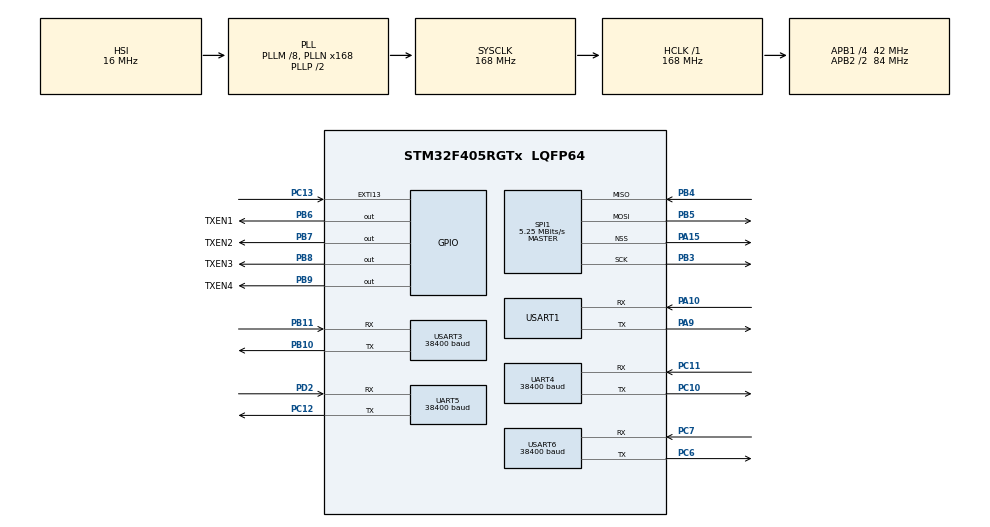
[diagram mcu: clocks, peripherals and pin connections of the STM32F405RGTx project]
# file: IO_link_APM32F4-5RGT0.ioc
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Dma.Request0=USART1_TX
Dma.Request1=USART1_RX
Dma.Request2=UART5_RX
Dma.Request3=UART4_RX
Dma.Request4=USART3_RX
Dma.Request5=USART6_RX
Dma.UART4_RX.3.Direction=DMA_PERIPH_TO_MEMORY
Dma.UART4_RX.3.FIFOMode=DMA_FIFOMODE_DISABLE
Dma.UART4_RX.3.Instance=DMA1_Stream2
Dma.UART4_RX.3.MemDataAlignment=DMA_MDATAALIGN_BYTE
Dma.UART4_RX.3.MemInc=DMA_MINC_ENABLE
Dma.UART4_RX.3.Mode=DMA_CIRCULAR
Dma.UART4_RX.3.PeriphDataAlignment=DMA_PDATAALIGN_BYTE
Dma.UART4_RX.3.PeriphInc=DMA_PINC_DISABLE
Dma.UART4_RX.3.Priority=DMA_PRIORITY_LOW
Dma.UART5_RX.2.Direction=DMA_PERIPH_TO_MEMORY
Dma.UART5_RX.2.FIFOMode=DMA_FIFOMODE_DISABLE
Dma.UART5_RX.2.Instance=DMA1_Stream0
Dma.UART5_RX.2.MemDataAlignment=DMA_MDATAALIGN_BYTE
Dma.UART5_RX.2.MemInc=DMA_MINC_ENABLE
Dma.UART5_RX.2.Mode=DMA_CIRCULAR
Dma.UART5_RX.2.PeriphDataAlignment=DMA_PDATAALIGN_BYTE
Dma.UART5_RX.2.PeriphInc=DMA_PINC_DISABLE
Dma.UART5_RX.2.Priority=DMA_PRIORITY_LOW
Dma.USART1_RX.1.Direction=DMA_PERIPH_TO_MEMORY
Dma.USART1_RX.1.FIFOMode=DMA_FIFOMODE_DISABLE
Dma.USART1_RX.1.Instance=DMA2_Stream2
Dma.USART1_RX.1.MemDataAlignment=DMA_MDATAALIGN_BYTE
Dma.USART1_RX.1.MemInc=DMA_MINC_ENABLE
Dma.USART1_RX.1.Mode=DMA_CIRCULAR
Dma.USART1_RX.1.PeriphDataAlignment=DMA_PDATAALIGN_BYTE
Dma.USART1_RX.1.PeriphInc=DMA_PINC_DISABLE
Dma.USART1_RX.1.Priority=DMA_PRIORITY_LOW
Dma.USART1_TX.0.Direction=DMA_MEMORY_TO_PERIPH
Dma.USART1_TX.0.FIFOMode=DMA_FIFOMODE_DISABLE
Dma.USART1_TX.0.Instance=DMA2_Stream7
Dma.USART1_TX.0.MemDataAlignment=DMA_MDATAALIGN_BYTE
Dma.USART1_TX.0.MemInc=DMA_MINC_ENABLE
Dma.USART1_TX.0.Mode=DMA_CIRCULAR
Dma.USART1_TX.0.PeriphDataAlignment=DMA_PDATAALIGN_BYTE
Dma.USART1_TX.0.PeriphInc=DMA_PINC_DISABLE
Dma.USART1_TX.0.Priority=DMA_PRIORITY_LOW
Dma.USART3_RX.4.Direction=DMA_PERIPH_TO_MEMORY
Dma.USART3_RX.4.FIFOMode=DMA_FIFOMODE_DISABLE
Dma.USART3_RX.4.Instance=DMA1_Stream1
Dma.USART3_RX.4.MemDataAlignment=DMA_MDATAALIGN_BYTE
Dma.USART3_RX.4.MemInc=DMA_MINC_ENABLE
Dma.USART3_RX.4.Mode=DMA_CIRCULAR
Dma.USART3_RX.4.PeriphDataAlignment=DMA_PDATAALIGN_BYTE
Dma.USART3_RX.4.PeriphInc=DMA_PINC_DISABLE
Dma.USART3_RX.4.Priority=DMA_PRIORITY_LOW
Dma.USART6_RX.5.Direction=DMA_PERIPH_TO_MEMORY
Dma.USART6_RX.5.FIFOMode=DMA_FIFOMODE_DISABLE
Dma.USART6_RX.5.Instance=DMA2_Stream1
Dma.USART6_RX.5.MemDataAlignment=DMA_MDATAALIGN_BYTE
Dma.USART6_RX.5.MemInc=DMA_MINC_ENABLE
Dma.USART6_RX.5.Mode=DMA_CIRCULAR
Dma.USART6_RX.5.PeriphDataAlignment=DMA_PDATAALIGN_BYTE
Dma.USART6_RX.5.PeriphInc=DMA_PINC_DISABLE
Dma.USART6_RX.5.Priority=DMA_PRIORITY_LOW
FREERTOS.Tasks01=defaultTask,24,128,StartDefaultTask,Default,NULL,Dynamic,NULL,NULL;DT35_1_App_task,24,256,DT35_1_App_Task,As external,NULL,Dynamic,NULL,NULL;DT35_2_App_task,24,256,DT35_2_App_Task,As external,NULL,Dynamic,NULL,NULL;DT35_3_App_task,24,256,DT35_3_App_Task,As external,NULL,Dynamic,NULL,NULL;DT35_4_App_task,24,256,DT35_4_App_Task,As external,NULL,Dynamic,NULL,NULL;DT35_App_task,24,256,DT35_App_Task,As external,NULL,Dynamic,NULL,NULL
Mcu.Family=STM32F4
Mcu.Name=STM32F405RGTx
Mcu.Package=LQFP64
NVIC.DMA1_Stream0_IRQn=true\:5\:0\:false\:false\:true\:true\:false\:true\:true
NVIC.DMA1_Stream1_IRQn=true\:5\:0\:false\:false\:true\:true\:false\:true\:true
NVIC.DMA1_Stream2_IRQn=true\:5\:0\:false\:false\:true\:true\:false\:true\:true
NVIC.DMA2_Stream1_IRQn=true\:5\:0\:false\:false\:true\:true\:false\:true\:true
NVIC.DMA2_Stream2_IRQn=true\:5\:0\:false\:false\:true\:true\:false\:true\:true
NVIC.DMA2_Stream7_IRQn=true\:5\:0\:false\:false\:true\:true\:false\:true\:true
NVIC.PriorityGroup=NVIC_PRIORITYGROUP_4
NVIC.SPI1_IRQn=true\:5\:0\:false\:false\:true\:true\:true\:true\:true
NVIC.TIM4_IRQn=true\:15\:0\:false\:false\:true\:false\:false\:true\:true
NVIC.TimeBase=TIM4_IRQn
NVIC.TimeBaseIP=TIM4
NVIC.USART1_IRQn=true\:5\:0\:false\:false\:true\:true\:true\:true\:true
PA10.Mode=Asynchronous
PA10.Signal=USART1_RX
PA13.Mode=Serial_Wire
PA13.Signal=SYS_JTMS-SWDIO
PA14.Mode=Serial_Wire
PA14.Signal=SYS_JTCK-SWCLK
PA15.Mode=NSS_Signal_Hard_Output
PA15.Signal=SPI1_NSS
PA9.Mode=Asynchronous
PA9.Signal=USART1_TX
PB10.Mode=Asynchronous
PB10.Signal=USART3_TX
PB11.Mode=Asynchronous
PB11.Signal=USART3_RX
PB3.Mode=Full_Duplex_Master
PB3.Signal=SPI1_SCK
PB4.Mode=Full_Duplex_Master
PB4.Signal=SPI1_MISO
PB5.Mode=Full_Duplex_Master
PB5.Signal=SPI1_MOSI
PB6.GPIO_Label=TXEN1
PB6.Signal=GPIO_Output
PB7.GPIO_Label=TXEN2
PB7.Signal=GPIO_Output
PB8.GPIO_Label=TXEN3
PB8.Signal=GPIO_Output
PB9.GPIO_Label=TXEN4
PB9.Signal=GPIO_Output
PC10.Mode=Asynchronous
PC10.Signal=UART4_TX
PC11.Mode=Asynchronous
PC11.Signal=UART4_RX
PC12.Mode=Asynchronous
PC12.Signal=UART5_TX
PC13-ANTI_TAMP.Signal=GPXTI13
PC6.Mode=Asynchronous
PC6.Signal=USART6_TX
PC7.Mode=Asynchronous
PC7.Signal=USART6_RX
PD2.Mode=Asynchronous
PD2.Signal=UART5_RX
PH0-OSC_IN.Mode=HSE-External-Oscillator
PH0-OSC_IN.Signal=RCC_OSC_IN
PH1-OSC_OUT.Mode=HSE-External-Oscillator
PH1-OSC_OUT.Signal=RCC_OSC_OUT
ProjectManager.HeapSize=0x200
ProjectManager.StackSize=0x400
ProjectManager.TargetToolchain=MDK-ARM V5.32
RCC.48MHZClocksFreq_Value=84000000
RCC.AHBFreq_Value=168000000
RCC.APB1CLKDivider=RCC_HCLK_DIV4
RCC.APB1Freq_Value=42000000
RCC.APB1TimFreq_Value=84000000
RCC.APB2CLKDivider=RCC_HCLK_DIV2
RCC.APB2Freq_Value=84000000
RCC.APB2TimFreq_Value=168000000
RCC.CortexFreq_Value=168000000
RCC.HCLKFreq_Value=168000000
RCC.HSE_VALUE=8000000
RCC.HSI_VALUE=16000000
RCC.LSE_VALUE=32768
RCC.PLLM=8
RCC.PLLN=168
RCC.SYSCLKFreq_VALUE=168000000
RCC.SYSCLKSource=RCC_SYSCLKSOURCE_PLLCLK
RCC.VCOOutputFreq_Value=336000000
SPI1.BaudRatePrescaler=SPI_BAUDRATEPRESCALER_16
SPI1.CalculateBaudRate=5.25 MBits/s
SPI1.Direction=SPI_DIRECTION_2LINES
SPI1.Mode=SPI_MODE_MASTER
SPI1.VirtualNSS=VM_NSSHARD
SPI1.VirtualType=VM_MASTER
UART4.BaudRate=38400
UART4.Parity=PARITY_EVEN
UART4.VirtualMode=Asynchronous
UART4.WordLength=WORDLENGTH_9B
UART5.BaudRate=38400
UART5.Parity=PARITY_EVEN
UART5.VirtualMode=Asynchronous
UART5.WordLength=WORDLENGTH_9B
USART1.VirtualMode=VM_ASYNC
USART3.BaudRate=38400
USART3.Parity=PARITY_EVEN
USART3.VirtualMode=VM_ASYNC
USART3.WordLength=WORDLENGTH_9B
USART6.BaudRate=38400
USART6.Parity=PARITY_EVEN
USART6.VirtualMode=VM_ASYNC
USART6.WordLength=WORDLENGTH_9B
VP_FREERTOS_VS_CMSIS_V2.Mode=CMSIS_V2
VP_SYS_VS_tim4.Mode=TIM4
board=custom

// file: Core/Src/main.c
/* USER CODE BEGIN Header */
/**
  ******************************************************************************
  * @file           : main.c
  * @brief          : Main program body
  ******************************************************************************
  * @attention
  *
  * Copyright (c) 2026 STMicroelectronics.
  * All rights reserved.
  *
  * This software is licensed under terms that can be found in the LICENSE file
  * in the root directory of this software component.
  * If no LICENSE file comes with this software, it is provided AS-IS.
  *
  ******************************************************************************
  */
/* USER CODE END Header */
#include "main.h"
#include "cmsis_os.h"
#include "dma.h"
#include "spi.h"
#include "usart.h"
#include "gpio.h"

/* USER CODE BEGIN Includes */
#include "iol_port_hal.h"
#include "app_dt35.h"

/* USER CODE END Includes */

void SystemClock_Config(void);
void MX_FREERTOS_Init(void);

int main(void)
{

  /* MCU Configuration--------------------------------------------------------*/

  /* Reset of all peripherals, Initializes the Flash interface and the Systick. */
     HAL_Init();

  /* Configure the system clock */
  SystemClock_Config();

  /* Initialize all configured peripherals */
  MX_GPIO_Init();
  MX_DMA_Init();
  MX_SPI1_Init();
  MX_USART1_UART_Init();
  MX_UART5_Init();
  MX_UART4_Init();
  MX_USART3_UART_Init();
  MX_USART6_UART_Init();
  /* USER CODE BEGIN 2 */
  IOL_HAL_Init();
  (void)DT35_Init();

  /* USER CODE END 2 */

  /* Init scheduler */
  osKernelInitialize();  /* Call init function for freertos objects (in cmsis_os2.c) */
  MX_FREERTOS_Init();

  /* Start scheduler */
  osKernelStart();

  /* We should never get here as control is now taken by the scheduler */

  /* Infinite loop */
  while (1)
  {

  }
}

void SystemClock_Config(void)
{
  RCC_OscInitTypeDef RCC_OscInitStruct = {0};
  RCC_ClkInitTypeDef RCC_ClkInitStruct = {0};

  /** Configure the main internal regulator output voltage
  */
  __HAL_RCC_PWR_CLK_ENABLE();
  __HAL_PWR_VOLTAGESCALING_CONFIG(PWR_REGULATOR_VOLTAGE_SCALE1);

  /** Initializes the RCC Oscillators according to the specified parameters
  * in the RCC_OscInitTypeDef structure.
  */
  RCC_OscInitStruct.OscillatorType = RCC_OSCILLATORTYPE_HSI;
  RCC_OscInitStruct.HSIState = RCC_HSI_ON;
  RCC_OscInitStruct.HSICalibrationValue = RCC_HSICALIBRATION_DEFAULT;
  RCC_OscInitStruct.PLL.PLLState = RCC_PLL_ON;
  RCC_OscInitStruct.PLL.PLLSource = RCC_PLLSOURCE_HSI;
  RCC_OscInitStruct.PLL.PLLM = 8;
  RCC_OscInitStruct.PLL.PLLN = 168;
  RCC_OscInitStruct.PLL.PLLP = RCC_PLLP_DIV2;
  RCC_OscInitStruct.PLL.PLLQ = 4;
  if (HAL_RCC_OscConfig(&RCC_OscInitStruct) != HAL_OK)
  {
    Error_Handler();
  }

  /** Initializes the CPU, AHB and APB buses clocks
  */
  RCC_ClkInitStruct.ClockType = RCC_CLOCKTYPE_HCLK|RCC_CLOCKTYPE_SYSCLK
                              |RCC_CLOCKTYPE_PCLK1|RCC_CLOCKTYPE_PCLK2;
  RCC_ClkInitStruct.SYSCLKSource = RCC_SYSCLKSOURCE_PLLCLK;
  RCC_ClkInitStruct.AHBCLKDivider = RCC_SYSCLK_DIV1;
  RCC_ClkInitStruct.APB1CLKDivider = RCC_HCLK_DIV4;
  RCC_ClkInitStruct.APB2CLKDivider = RCC_HCLK_DIV2;

  if (HAL_RCC_ClockConfig(&RCC_ClkInitStruct, FLASH_LATENCY_5) != HAL_OK)
  {
    Error_Handler();
  }
}

void HAL_TIM_PeriodElapsedCallback(TIM_HandleTypeDef *htim)
{
  if (htim->Instance == TIM4)
  {
    HAL_IncTick();
  }
}

void Error_Handler(void)
{
  __disable_irq();
  while (1)
  {
  }
}

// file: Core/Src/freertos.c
/* USER CODE BEGIN Header */
/**
  ******************************************************************************
  * File Name          : freertos.c
  * Description        : Code for freertos applications
  ******************************************************************************
  * @attention
  *
  * Copyright (c) 2026 STMicroelectronics.
  * All rights reserved.
  *
  * This software is licensed under terms that can be found in the LICENSE file
  * in the root directory of this software component.
  * If no LICENSE file comes with this software, it is provided AS-IS.
  *
  ******************************************************************************
  */
/* USER CODE END Header */

#include "FreeRTOS.h"
#include "task.h"
#include "main.h"
#include "iol_port_hal.h"
#include "cmsis_os.h"

/* Definitions for defaultTask */
osThreadId_t defaultTaskHandle;
const osThreadAttr_t defaultTask_attributes = {
  .name = "defaultTask",
  .stack_size = 128 * 4,
  .priority = (osPriority_t) osPriorityNormal,
};
/* Definitions for DT35_1_App_task */
osThreadId_t DT35_1_App_taskHandle;
const osThreadAttr_t DT35_1_App_task_attributes = {
  .name = "DT35_1_App_task",
  .stack_size = 256 * 4,
  .priority = (osPriority_t) osPriorityNormal,
};
/* Definitions for DT35_2_App_task */
osThreadId_t DT35_2_App_taskHandle;
const osThreadAttr_t DT35_2_App_task_attributes = {
  .name = "DT35_2_App_task",
  .stack_size = 256 * 4,
  .priority = (osPriority_t) osPriorityNormal,
};
/* Definitions for DT35_3_App_task */
osThreadId_t DT35_3_App_taskHandle;
const osThreadAttr_t DT35_3_App_task_attributes = {
  .name = "DT35_3_App_task",
  .stack_size = 256 * 4,
  .priority = (osPriority_t) osPriorityNormal,
};
/* Definitions for DT35_4_App_task */
osThreadId_t DT35_4_App_taskHandle;
const osThreadAttr_t DT35_4_App_task_attributes = {
  .name = "DT35_4_App_task",
  .stack_size = 256 * 4,
  .priority = (osPriority_t) osPriorityNormal,
};
/* Definitions for DT35_App_task */
osThreadId_t DT35_App_taskHandle;
const osThreadAttr_t DT35_App_task_attributes = {
  .name = "DT35_App_task",
  .stack_size = 256 * 4,
  .priority = (osPriority_t) osPriorityNormal,
};

void StartDefaultTask(void *argument);
extern void DT35_1_App_Task(void *argument);
extern void DT35_2_App_Task(void *argument);
extern void DT35_3_App_Task(void *argument);
extern void DT35_4_App_Task(void *argument);
extern void DT35_App_Task(void *argument);

void MX_FREERTOS_Init(void); /* (MISRA C 2004 rule 8.1) */

void MX_FREERTOS_Init(void) {
  IOL_HAL_RtosInit();

  /* Create the thread(s) */
  /* creation of defaultTask */
  defaultTaskHandle = osThreadNew(StartDefaultTask, NULL, &defaultTask_attributes);

  /* creation of DT35_1_App_task */
  DT35_1_App_taskHandle = osThreadNew(DT35_1_App_Task, NULL, &DT35_1_App_task_attributes);

  /* creation of DT35_2_App_task */
  DT35_2_App_taskHandle = osThreadNew(DT35_2_App_Task, NULL, &DT35_2_App_task_attributes);

  /* creation of DT35_3_App_task */
  DT35_3_App_taskHandle = osThreadNew(DT35_3_App_Task, NULL, &DT35_3_App_task_attributes);

  /* creation of DT35_4_App_task */
  DT35_4_App_taskHandle = osThreadNew(DT35_4_App_Task, NULL, &DT35_4_App_task_attributes);

  /* creation of DT35_App_task */
  DT35_App_taskHandle = osThreadNew(DT35_App_Task, NULL, &DT35_App_task_attributes);

  if ((defaultTaskHandle == NULL) || (DT35_1_App_taskHandle == NULL) ||
      (DT35_2_App_taskHandle == NULL) || (DT35_3_App_taskHandle == NULL) ||
      (DT35_4_App_taskHandle == NULL) || (DT35_App_taskHandle == NULL)) {
    Error_Handler();
  }

}

void StartDefaultTask(void *argument)
{
  for(;;)
  {
    osDelay(1);
  }
}

/* USER CODE BEGIN Application */

void vApplicationStackOverflowHook(TaskHandle_t xTask, char *pcTaskName)
{
    (void)xTask;
    (void)pcTaskName;
    taskDISABLE_INTERRUPTS();
    for (;;) { }
}

void vApplicationMallocFailedHook(void)
{
    taskDISABLE_INTERRUPTS();
    for (;;) { }
}

/* USER CODE END Application */
